# CH564 register map
Vendor: WCH Ltd.; File version: 1.0
Registers are 8-bit, read-write, reset 0x0 unless marked. A register's access mark holds for its fields unless they carry their own. Offsets are from the block's base; [hi:lo] are bit positions.

## TIMER3 — TMR3 register
Base 0x40408C00
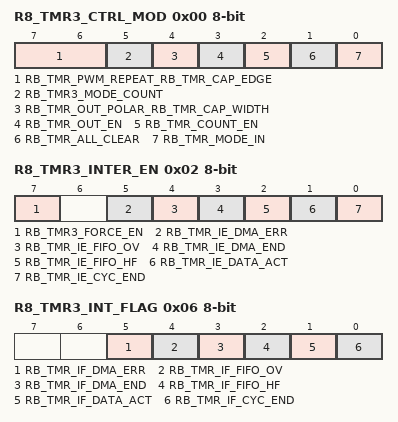
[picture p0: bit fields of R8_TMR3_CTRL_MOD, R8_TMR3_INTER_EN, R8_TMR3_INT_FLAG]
0x00 R8_TMR3_CTRL_MOD — TMR3 mode control
  [7:6] RB_TMR_PWM_REPEAT_RB_TMR_CAP_EDGE — timer PWM repeat mode / timer capture edge mode
  [5] RB_TMR3_MODE_COUNT — external clock counter mode
  [4] RB_TMR_OUT_POLAR_RB_TMR_CAP_WIDTH — timer PWM output polarity / Capture pulse width
  [3] RB_TMR_OUT_EN — timer output enable
  [2] RB_TMR_COUNT_EN — timer count enable
  [1] RB_TMR_ALL_CLEAR — force clear timer FIFO and count
  [0] RB_TMR_MODE_IN — timer in mode
0x02 R8_TMR3_INTER_EN — TMR3 interrupt enable
  [7] RB_TMR3_FORCE_EN — Forcibly enable TIMER0,TIMER1 and TIMER2 at the same time
  [5] RB_TMR_IE_DMA_ERR — enable DMA error responde interrupt
  [4] RB_TMR_IE_FIFO_OV — enable interrupt for timer FIFO overflow
  [3] RB_TMR_IE_DMA_END — enable interrupt for timer DMA completion
  [2] RB_TMR_IE_FIFO_HF — enable interrupt for timer FIFO half (capture fifo >=4 or PWM fifo lower than3)
  [1] RB_TMR_IE_DATA_ACT — enable interrupt for timer capture input action or PWM trigger
  [0] RB_TMR_IE_CYC_END — enable interrupt for timer capture count timeout or PWM cycle end
0x06 R8_TMR3_INT_FLAG — TMR3 interrupt flag
  [5] RB_TMR_IF_DMA_ERR — DMA error responde flag
  [4] RB_TMR_IF_FIFO_OV — interrupt flag for timer FIFO overflow
  [3] RB_TMR_IF_DMA_END — interrupt flag for timer DMA completion
  [2] RB_TMR_IF_FIFO_HF — interrupt flag for timer FIFO half
  [1] RB_TMR_IF_DATA_ACT — interrupt flag for timer capture input action or PWM trigger
  [0] RB_TMR_IF_CYC_END — interrupt flag for timer capture count timeout or PWM cycle end
0x07 R8_TMR3_FIFO_COUNT ro — TMR3 FIFO count status
  [7:0] TMR3_FIFO_COUNT
0x08 R32_TMR3_COUNT 32-bit ro — TMR3 current count
  [27:0] TMR3_COUNT
0x0C R32_TMR3_CNT_END 32-bit — TMR3 end count value, only low 28 bit
  [27:0] TMR3_CNT_END — The number of timer ticks in timer mode
0x10 R32_TMR3_FIFO 32-bit read-only/write-only — TMR3 FIFO register, only low 28 bit
  [27:0] TMR3_FIFO — TMR3 FIFO current count

## SPI0
Base 0x4040C000
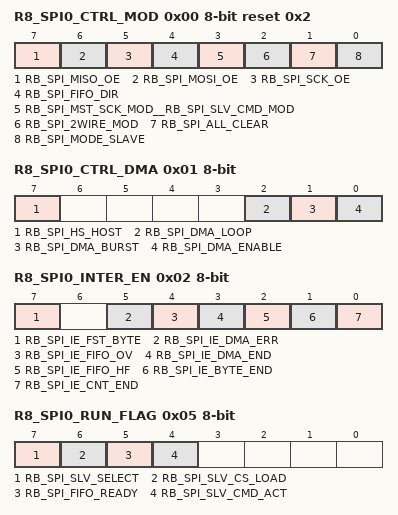
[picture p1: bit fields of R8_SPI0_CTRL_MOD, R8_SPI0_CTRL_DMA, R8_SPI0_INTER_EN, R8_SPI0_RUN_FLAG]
0x00 R8_SPI0_CTRL_MOD reset 0x2 — SPI0 mode control
  [7] RB_SPI_MISO_OE — SPI MISO output enable
  [6] RB_SPI_MOSI_OE — SPI MOSI output enable
  [5] RB_SPI_SCK_OE — SPI SCK output enable
  [4] RB_SPI_FIFO_DIR — SPI FIFO direction
  [3] RB_SPI_MST_SCK_MOD__RB_SPI_SLV_CMD_MOD — SPI master clock mode _ SPI slave command mode
  [2] RB_SPI_2WIRE_MOD — SPI enable 2 wire mode
  [1] RB_SPI_ALL_CLEAR — force clear SPI FIFO and count
  [0] RB_SPI_MODE_SLAVE — SPI slave mode
0x01 R8_SPI0_CTRL_DMA — SPI0 DMA control
  [7] RB_SPI_HS_HOST — High speed host receive mode control bit
  [2] RB_SPI_DMA_LOOP — SPI DMA address loop enable
  [1] RB_SPI_DMA_BURST — DMA block operates on the enable bit
  [0] RB_SPI_DMA_ENABLE — SPI DMA enable
0x02 R8_SPI0_INTER_EN — SPI0 interrupt enable
  [7] RB_SPI_IE_FST_BYTE — enable interrupt for SPI slave mode first byte received
  [5] RB_SPI_IE_DMA_ERR — enable interrupt for DMA transfer error
  [4] RB_SPI_IE_FIFO_OV — enable interrupt for SPI FIFO overflow
  [3] RB_SPI_IE_DMA_END — enable interrupt for SPI DMA completion
  [2] RB_SPI_IE_FIFO_HF — enable interrupt for SPI FIFO half
  [1] RB_SPI_IE_BYTE_END — enable interrupt for SPI single byte exchanged
  [0] RB_SPI_IE_CNT_END — enable interrupt for SPI total byte count end
0x03 R8_SPI0_CLOCK_DIV_R8_SPI0_SLAVE_PRE reset 0x10 — SPI0 master clock divisor / SPI0 slave preset value
  [7:0] SPI0_CLOCK_DIV_SPI0_SLAVE_PRE — master clock divisor / SPI0 slave preset value
0x04 R8_SPI0_BUFFER — SPI0 data buffer
  [7:0] SPI0_BUFFER — SPI data buffer
0x05 R8_SPI0_RUN_FLAG ro — SPI0 work flag
  [7] RB_SPI_SLV_SELECT — SPI slave selection status
  [6] RB_SPI_SLV_CS_LOAD — SPI slave chip-select loading status
  [5] RB_SPI_FIFO_READY — SPI FIFO ready status
  [4] RB_SPI_SLV_CMD_ACT — SPI slave command flag
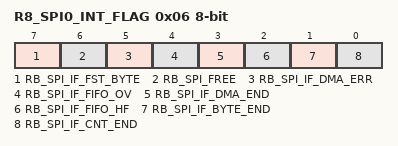
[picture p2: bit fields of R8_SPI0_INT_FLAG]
0x06 R8_SPI0_INT_FLAG access per field — SPI0 interrupt flag
  [7] RB_SPI_IF_FST_BYTE rw — interrupt flag for SPI slave mode first byte received
  [6] RB_SPI_FREE ro — current SPI free status
  [5] RB_SPI_IF_DMA_ERR rw — interrupt flag for SPI DMA transfer error
  [4] RB_SPI_IF_FIFO_OV rw — interrupt flag for SPI FIFO overflow
  [3] RB_SPI_IF_DMA_END rw — interrupt flag for SPI DMA completion
  [2] RB_SPI_IF_FIFO_HF rw — interrupt flag for SPI FIFO half
  [1] RB_SPI_IF_BYTE_END rw — interrupt flag for SPI byte exchanged
  [0] RB_SPI_IF_CNT_END rw — interrupt flag for SPI total byte count end
0x07 R8_SPI0_FIFO_COUNT ro — SPI0 FIFO count status
  [7:0] SPI0_FIFO_COUNT — SPI FIFO count status
0x08 R8_SPI0_RESET_CMD — SPI0 reset command word register
  [7:0] SPI0_RESET_CMD — A global reset is generated when this command is received
0x09 R8_SPI0_BUSY — SPI0 busy flag register
  [0] SPI0_BUSY — busy flag bit
0x0C R16_SPI0_TOTAL_CNT 16-bit — SPI0 total byte count, only low 12 bit
  [11:0] SPI0_TOTAL_CNT — SPI total byte count, only low 12 bit
0x10 R8_SPI0_FIFO read-only/write-only — SPI0 FIFO register
  [7:0] SPI0_FIFO — SPI FIFO register
0x13 R8_SPI0_FIFO_COUNT1 ro — SPI0 FIFO count status
  [7:0] SPI0_FIFO_COUNT1 — SPI FIFO count statu
0x14 R32_SPI0_DMA_NOW 32-bit — SPI0 DMA current address
  [17:0] SPI0_DMA_NOW — SPI DMA current address
0x18 R32_SPI0_DMA_BEG 32-bit — SPI0 DMA begin address
  [17:0] SPI0_DMA_BEG — SPI DMA begin address
0x1C R32_SPI0_DMA_END 32-bit — SPI0 DMA end address
  [17:0] SPI0_DMA_END — SPI DMA end address
